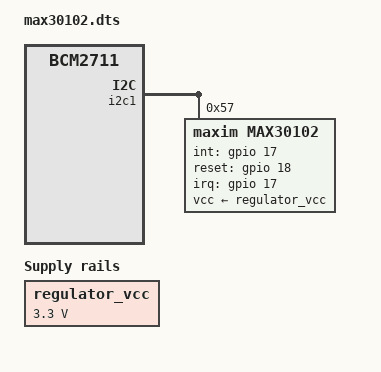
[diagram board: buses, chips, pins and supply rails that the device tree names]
/dts-v1/;
/plugin/;

/ {
    compatible = "brcm,bcm2711";

    fragment@0 {
        target = <&i2c1>;
        __overlay__ {
            status = "okay";

            max30102: max30102@57 {
                compatible = "maxim,max30102";
                reg = <0x57>;
                int-gpios = <&gpio 17 0>;
                reset-gpios = <&gpio 18 0>;
                led1-current-mA = <6>;
                led2-current-mA = <6>;
                interrupt-parent = <&gpio>;
                interrupts = <17 IRQ_TYPE_EDGE_FALLING>;
                vcc-supply = <&regulator_vcc>;
                #io-channel-cells = <0>;
                phandle = <0x30102>;
            };
        };
    };

    fragment@1 {
        target-path = "/";
        __overlay__ {
            regulator_vcc: regulator-vcc {
                compatible = "regulator-fixed";
                regulator-name = "vcc";
                regulator-min-microvolt = <3300000>;
                regulator-max-microvolt = <3300000>;
                regulator-always-on;
            };
        };
    };
};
